AUTOSAR XML (schema 314)
# Copyright © Vector Informatik GmbH 2011
# Please contact Vector Informatik whenever you need further information concerning the license conditions.
package /VehicleProject
  system System: fibex-element=[CAN00, LIN00, FlexRay, MyECU, MyECU, MyECU__CAN00_Rx, MyECU__CAN00_Tx, MyECU__FlexRay_Rx, MyECU__FlexRay_Tx, MyECU__LIN00_Rx, MyECU__LIN00_Tx, Dummy_RearECU, Frame_LinTr_MyECU__LIN00, Frame_LinTr_RearECU__LIN00, MasterReq__LIN00, msg_diag_Request_MyECU__CAN00, msg_diag_RequestGlobal__CAN00, msg_diag_Response_MyECU__CAN00, msg_diag_Uudt_Response_MyECU__CAN00, msg_nm_MyECU__CAN00, msg_Receive__CAN00, msg_TxCycle10__CAN00, msg_TxMulti100__CAN00, msg_XCP_Request__CAN00, msg_XCP_Response__CAN00, nm_MyECU_Fr, SlaveResp__LIN00, TpRouting_Rx, TpRouting_Tx, Transmit_MyECU, Frame_LinTr_MyECU__LIN00, Frame_LinTr_RearECU__LIN00, msg_Receive__CAN00, msg_TxCycle10__CAN00, msg_TxMulti100_Mx00__CAN00, msg_TxMulti100_Mx01__CAN00, msg_XCP_Request__CAN00, msg_XCP_Response__CAN00, PDU_Dummy_RearECU, PDU_Transmit_MyECU, msg_TxMulti100__CAN00, MasterReq__LIN00, msg_diag_Request_MyECU__CAN00, msg_diag_RequestGlobal__CAN00, msg_diag_Response_MyECU__CAN00, msg_diag_Uudt_Response_MyECU__CAN00, SlaveResp__LIN00, msg_nm_MyECU__CAN00, PDU_nm_MyECU_Fr, MasterReq_Tp__LIN00, msg_diag_Request_MyECU_Tp__CAN00, msg_diag_RequestGlobal_Tp__CAN00, msg_diag_Response_MyECU_Tp__CAN00, msg_diag_Uudt_Response_MyECU_Tp__CAN00, PDU_TpRouting_Rx_Tp, PDU_TpRouting_Tx_Tp, SlaveResp_Tp__LIN00, Sig_ErrBit_RearECU__Frame_LinTr_RearECU__LIN00, Sig_LinTr_MyECU__Frame_LinTr_MyECU__LIN00, Sig_LinTr_RearECU__Frame_LinTr_RearECU__LIN00, Signal_Dummy__PDU_Dummy_RearECU, Signal_RearInteriorLight__msg_Receive__CAN00, Signal_RearLeftDoor__msg_Receive__CAN00, Signal_RearRightDoor__msg_Receive__CAN00, Signal_SwitchRearInteriorLight__PDU_Transmit_MyECU, Signal_TxCycle10__msg_TxCycle10__CAN00, Signal_TxMulti_0_0_Mx00__msg_TxMulti100__CAN00, Signal_TxMulti0_1_Mx00__msg_TxMulti100__CAN00, Signal_TxMulti0_2_Mx00__msg_TxMulti100__CAN00, Signal_TxMulti0_3_Mx00__msg_TxMulti100__CAN00, Signal_TxMulti1_0_Mx01__msg_TxMulti100__CAN00, Signal_TxMulti1_1_Mx01__msg_TxMulti100__CAN00, Signal_TxMulti1_2_Mx01__msg_TxMulti100__CAN00, Signal_TxMulti1_3_Mx01__msg_TxMulti100__CAN00, Signal_TxMulti1_4_Mx01__msg_TxMulti100__CAN00, Signal_TxMultiplexor_Mx00__msg_TxMulti100__CAN00, Signal_TxMultiplexor_Mx01__msg_TxMulti100__CAN00]
package /Cluster
  can cluster CAN00: protocol-name=CAN, speed=500000, nm-lower-can-id=1024, nm-repeat-message-state-time=0.4, nm-timeout-time=1, nm-upper-can-id=1087, nm-wait-bus-sleep-time=0.75
    physical channel CHNL
      frame msg_diag_Request_MyECU__CAN00: id 0x610, frame-length=8, can-addressing-mode=STANDARD
        n pdu msg_diag_Request_MyECU_Tp__CAN00: length=64
      frame msg_diag_RequestGlobal__CAN00: id 0x614, frame-length=8, can-addressing-mode=STANDARD
        n pdu msg_diag_RequestGlobal_Tp__CAN00: length=64
      frame msg_diag_Response_MyECU__CAN00: id 0x612, frame-length=8, can-addressing-mode=STANDARD
        n pdu msg_diag_Response_MyECU_Tp__CAN00: length=64
      frame msg_diag_Uudt_Response_MyECU__CAN00: id 0x616, frame-length=8, can-addressing-mode=STANDARD
        n pdu msg_diag_Uudt_Response_MyECU_Tp__CAN00: length=64
      frame msg_nm_MyECU__CAN00: id 0x400, frame-length=8, can-addressing-mode=STANDARD
        nm pdu msg_nm_MyECU__CAN00: length=64
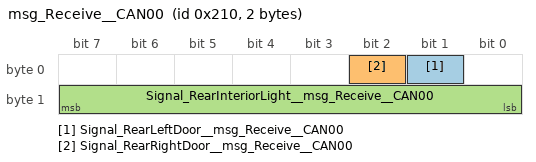
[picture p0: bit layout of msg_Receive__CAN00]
      frame msg_Receive__CAN00: id 0x210, frame-length=2, can-addressing-mode=STANDARD
        pdu msg_Receive__CAN00: length=16, cyclic-timing={repeating-time=0.1, starting-time=0}, minimum-delay=0, transmission-mode-false-timing=cyclic-timing={repeating-time=0.1, starting-time=0}
          signal Signal_RearLeftDoor__msg_Receive__CAN00: start 1, 1 bit, little-endian, data-type=DT_Signal_RearLeftDoor, init-value=C_Signal_RearLeftDoor, transfer-property=PENDING
          signal Signal_RearRightDoor__msg_Receive__CAN00: start 2, 1 bit, little-endian, data-type=DT_Signal_RearRightDoor, init-value=C_Signal_RearRightDoor, transfer-property=PENDING
          signal Signal_RearInteriorLight__msg_Receive__CAN00: start 8, 8 bit, little-endian, data-type=DT_Signal_RearInteriorLight, init-value=C_Signal_RearInteriorLight, transfer-property=PENDING
      frame msg_TxCycle10__CAN00: id 0x268, frame-length=8, can-addressing-mode=STANDARD
        pdu msg_TxCycle10__CAN00: length=64, cyclic-timing={repeating-time=0.01, starting-time=0}, minimum-delay=0, transmission-mode-false-timing=cyclic-timing={repeating-time=0.01, starting-time=0}
          signal Signal_TxCycle10__msg_TxCycle10__CAN00: start 0, 32 bit, little-endian, data-type=DT_Signal_TxCycle10, init-value=C_Signal_TxCycle10, transfer-property=PENDING
      frame msg_TxMulti100__CAN00: id 0x266, frame-length=8, can-addressing-mode=STANDARD
        multiplexed i pdu msg_TxMulti100__CAN00:
          length=64
          dynamic-part={segment-position{segment-byte-order=little-endian, segment-length=48, segment-position=0}, dynamic-part-alternatives=[{i-pdu=msg_TxMulti100_Mx00__CAN00, initial-dynamic-part=true, selector-field-code=0}, {i-pdu=msg_TxMulti100_Mx01__CAN00, initial-dynamic-part=false, selector-field-code=1}]}
          selector-field-byte-order=little-endian
          selector-field-length=3
          selector-field-start-position=0
      frame msg_XCP_Request__CAN00: id 0x703, frame-length=8, can-addressing-mode=STANDARD
        pdu msg_XCP_Request__CAN00: length=64
      frame msg_XCP_Response__CAN00: id 0x704, frame-length=8, can-addressing-mode=STANDARD
        pdu msg_XCP_Response__CAN00: length=64
      pdu triggering PT_msg_diag_Request_MyECU: pdu=msg_diag_Request_MyECU__CAN00
      pdu triggering PT_msg_diag_RequestGlobal: pdu=msg_diag_RequestGlobal__CAN00
      pdu triggering PT_msg_diag_Response_MyECU: pdu=msg_diag_Response_MyECU__CAN00
      pdu triggering PT_msg_diag_Uudt_Response_MyECU: pdu=msg_diag_Uudt_Response_MyECU__CAN00
      pdu triggering PT_msg_TxMulti100_Mx00: pdu=msg_TxMulti100_Mx00__CAN00
      pdu triggering PT_msg_TxMulti100_Mx01: pdu=msg_TxMulti100_Mx01__CAN00
      tp-channels:
        addressing-format=STANDARD, data-pdu=msg_diag_RequestGlobal_Tp__CAN00, multicast-addressing=true, padding-activation=true, tp-sdu=msg_diag_RequestGlobal__CAN00
        addressing-format=STANDARD, data-pdu=msg_diag_Response_MyECU_Tp__CAN00, flow-control-pdu=msg_diag_Request_MyECU_Tp__CAN00, multicast-addressing=false, padding-activation=true, source=CN_CAN00, tp-sdu=msg_diag_Response_MyECU__CAN00
        addressing-format=STANDARD, data-pdu=msg_diag_Request_MyECU_Tp__CAN00, flow-control-pdu=msg_diag_Response_MyECU_Tp__CAN00, multicast-addressing=false, padding-activation=true, target=CN_CAN00, tp-sdu=msg_diag_Request_MyECU__CAN00
  lin cluster LIN00: protocol-name=LIN, protocol-version=2.0, speed=19200  # /*************************************************************************************/ // // Description: LIN Description file created using Vector's DaVinci Network Designer // Created: 07 Jul 2009 09:46:32 // Author: vishgo // Version: 0.0 // /*************************************************************************************/
    physical channel CHNL
      frame Frame_LinTr_MyECU__LIN00: id 0x11, from MyECU, frame-length=1, checksum-type=CLASSIC, relatively-scheduled-timing{delay=0.005, position-in-table=0, schedule-table=Normal}
        pdu Frame_LinTr_MyECU__LIN00: length=8
          signal Sig_LinTr_MyECU__Frame_LinTr_MyECU__LIN00: start 0, 8 bit, little-endian, data-type=DT_Sig_LinTr_MyECU, init-value=C_Sig_LinTr_MyECU
      frame Frame_LinTr_RearECU__LIN00: id 0x12, to MyECU, frame-length=1, checksum-type=CLASSIC, relatively-scheduled-timing{delay=0.005, position-in-table=1, schedule-table=Normal}
        pdu Frame_LinTr_RearECU__LIN00: length=8
          signal Sig_LinTr_RearECU__Frame_LinTr_RearECU__LIN00: start 0, 7 bit, little-endian, data-type=DT_Sig_LinTr_RearECU, init-value=C_Sig_LinTr_RearECU, to MyECU
          signal Sig_ErrBit_RearECU__Frame_LinTr_RearECU__LIN00: start 7, 1 bit, little-endian, data-type=DT_Sig_ErrBit_RearECU, init-value=C_Sig_ErrBit_RearECU, to MyECU
      frame MasterReq__LIN00: id 0x3C, from MyECU, frame-length=8, checksum-type=CLASSIC, relatively-scheduled-timing{delay=0.08, position-in-table=0, schedule-table=Diagnose}
        n pdu MasterReq_Tp__LIN00: length=64
      frame SlaveResp__LIN00: id 0x3D, to MyECU, frame-length=8, checksum-type=CLASSIC, relatively-scheduled-timing{delay=0.08, position-in-table=1, schedule-table=Diagnose}
        n pdu SlaveResp_Tp__LIN00: length=64
      pdu triggering PT_MasterReq: pdu=MasterReq__LIN00, from MyECU
      pdu triggering PT_SlaveResp: pdu=SlaveResp__LIN00, to MyECU
    lin schedule table Diagnose: priority=255, run-mode=RUN-CONTINUOUS
    lin schedule table Normal: priority=255, run-mode=RUN-CONTINUOUS
  flexray cluster FlexRay:
    protocol-name=FlexRay
    protocol-version=3.0
    speed=10000000
    action-point-offset=3
    bit=1E-07
    cas-rx-low-max=99
    cold-start-attempts=31
    cycle=0.005
    dynamic-slot-idle-phase=1
    listen-noise=2
    macro-per-cycle=5000
    macrotick-duration=1E-06
    max-initialisation-error=3.024E-06
    max-without-clock-correction-fatal=1
    max-without-clock-correction-passive=1
    minislot-action-point-offset=3
    minislot-duration=7
    network-idle-time=105
    network-management-vector-length=0
    number-of-minislots=267
    number-of-static-slots=89
    offset-correction-start=4956
    payload-length-static=8
    sample-clock-period=1.25E-08
    static-slot-duration=34
    symbol-window=0
    sync-node-max=9
    transmission-start-sequence-duration=15
    wake-up-symbol-rx-idle=59
    wake-up-symbol-rx-low=55
    wake-up-symbol-rx-window=301
    wake-up-symbol-tx-idle=180
    wake-up-symbol-tx-low=60
    flexray physical channel Channel_A: channel-name=CHANNEL-A
      frame Transmit_MyECU: from MyECU, frame-length=8, absolutely-scheduled-timing{communication-cycle=cycle-repetition={base-cycle=0, cycle-repetition=CYCLE-REPETITION-1}, slot-id=2}
        pdu PDU_Transmit_MyECU: length=64, cyclic-timing=repeating-time=0.1
          signal Signal_SwitchRearInteriorLight__PDU_Transmit_MyECU: start 0, 8 bit, little-endian, data-type=New_Coding_1, init-value=C_Signal_SwitchRearInteriorLight
      frame Dummy_RearECU: to MyECU, frame-length=16, absolutely-scheduled-timing{communication-cycle=cycle-repetition={base-cycle=0, cycle-repetition=CYCLE-REPETITION-1}, slot-id=3}
        pdu PDU_Dummy_RearECU: length=128, cyclic-timing=repeating-time=0.1
          signal Signal_Dummy__PDU_Dummy_RearECU: start 0, 8 bit, little-endian, data-type=New_Coding_2, init-value=C_Signal_Dummy, to MyECU
      frame nm_MyECU_Fr: from MyECU, frame-length=8, absolutely-scheduled-timing{communication-cycle=cycle-repetition={base-cycle=0, cycle-repetition=CYCLE-REPETITION-64}, slot-id=90}
        nm pdu PDU_nm_MyECU_Fr: length=64
      frame TpRouting_Tx: from MyECU, frame-length=16, absolutely-scheduled-timing{communication-cycle=cycle-repetition={base-cycle=0, cycle-repetition=CYCLE-REPETITION-4}, slot-id=97}
        n pdu PDU_TpRouting_Tx_Tp: length=128
      frame TpRouting_Rx: to MyECU, frame-length=16, absolutely-scheduled-timing{communication-cycle=cycle-repetition={base-cycle=0, cycle-repetition=CYCLE-REPETITION-4}, slot-id=99}
        n pdu PDU_TpRouting_Rx_Tp: length=128
package /ECU
  ecu instance MyECU: associated-i-pdu-group=[MyECU__CAN00_Rx, MyECU__CAN00_Tx, MyECU__FlexRay_Rx, MyECU__FlexRay_Tx, MyECU__LIN00_Rx, MyECU__LIN00_Tx], com-processing-period=0.001
    flexray communication controller MyECU:
      accepted-startup-range=242
      allow-halt-due-to-clock=true
      allow-passive-to-active=0
      cluster-drift-damping=2
      decoding-correction=72
      delay-compensation-a=1
      delay-compensation-b=1
      extern-offset-correction=0
      extern-rate-correction=0
      key-slot-id=2
      key-slot-used-for-start-up=true
      key-slot-used-for-sync=true
      latest-tx=1
      listen-timeout=401202
      macro-initial-offset-a=5
      macro-initial-offset-b=5
      max-drift=601
      maximum-dynamic-payload-length=127
      micro-initial-offset-a=7
      micro-initial-offset-b=7
      micro-per-cycle=200000
      microtick-duration=2.5E-08
      offset-correction-out=150
      rate-correction-out=601
      samples-per-microtick=2
      single-slot-enabled=false
      wake-up-pattern=63
    lin master CT_LIN00: time-base=0.001, time-base-jitter=0
    communication connector CN_LIN00: channel=LIN00/CHNL, comm-controller=CT_LIN00
    flex ray communication connector CN_Channel_A: channel=Channel_A, comm-controller=MyECU, wake-up-channel=false
package /Gateway
  gateway MyECU: ecu=MyECU
package /IPDUGroup
  6 x i pdu group:
    MyECU__CAN00_Rx: communication-direction=IN, i-pdu=msg_Receive__CAN00
    MyECU__CAN00_Tx: communication-direction=OUT, i-pdu=[msg_TxCycle10__CAN00, msg_TxMulti100_Mx00__CAN00, msg_TxMulti100_Mx01__CAN00]
    MyECU__FlexRay_Rx: communication-direction=IN, i-pdu=PDU_Dummy_RearECU
    MyECU__FlexRay_Tx: communication-direction=OUT, i-pdu=PDU_Transmit_MyECU
    MyECU__LIN00_Rx: communication-direction=IN, i-pdu=Frame_LinTr_RearECU__LIN00
    MyECU__LIN00_Tx: communication-direction=OUT, i-pdu=Frame_LinTr_MyECU__LIN00
package /PDU
  pdu msg_TxMulti100_Mx00__CAN00: length=64, cyclic-timing={repeating-time=0.2, starting-time=0}, minimum-delay=0
    signal Signal_TxMultiplexor_Mx00__msg_TxMulti100__CAN00: start 0, 3 bit, little-endian, data-type=DT_Signal_TxMultiplexor, init-value=C_Signal_TxMultiplexor_Mx00, transfer-property=PENDING
    signal Signal_TxMulti_0_0_Mx00__msg_TxMulti100__CAN00: start 8, 2 bit, little-endian, data-type=DT_Signal_TxMulti_0_0, init-value=C_Signal_TxMulti_0_0, transfer-property=PENDING
    signal Signal_TxMulti0_1_Mx00__msg_TxMulti100__CAN00: start 16, 8 bit, little-endian, data-type=DT_Signal_TxMulti0_1, init-value=C_Signal_TxMulti0_1, transfer-property=PENDING
    signal Signal_TxMulti0_2_Mx00__msg_TxMulti100__CAN00: start 24, 4 bit, little-endian, data-type=DT_Signal_TxMulti0_2, init-value=C_Signal_TxMulti0_2, transfer-property=PENDING
    signal Signal_TxMulti0_3_Mx00__msg_TxMulti100__CAN00: start 32, 8 bit, little-endian, data-type=DT_Signal_TxMulti0_3, init-value=C_Signal_TxMulti0_3, transfer-property=PENDING
  pdu msg_TxMulti100_Mx01__CAN00: length=64, cyclic-timing={repeating-time=0.2, starting-time=0.1}, minimum-delay=0
    signal Signal_TxMultiplexor_Mx01__msg_TxMulti100__CAN00: start 0, 3 bit, little-endian, data-type=DT_Signal_TxMultiplexor, init-value=C_Signal_TxMultiplexor_Mx01, transfer-property=PENDING
    signal Signal_TxMulti1_0_Mx01__msg_TxMulti100__CAN00: start 8, 8 bit, little-endian, data-type=DT_Signal_TxMulti1_0, init-value=C_Signal_TxMulti1_0, transfer-property=PENDING
    signal Signal_TxMulti1_1_Mx01__msg_TxMulti100__CAN00: start 16, 8 bit, little-endian, data-type=DT_Signal_TxMulti1_1, init-value=C_Signal_TxMulti1_1, transfer-property=PENDING
    signal Signal_TxMulti1_2_Mx01__msg_TxMulti100__CAN00: start 24, 8 bit, little-endian, data-type=DT_Signal_TxMulti1_2, init-value=C_Signal_TxMulti1_2, transfer-property=PENDING
    signal Signal_TxMulti1_3_Mx01__msg_TxMulti100__CAN00: start 32, 8 bit, little-endian, data-type=DT_Signal_TxMulti1_3, init-value=C_Signal_TxMulti1_3, transfer-property=PENDING
    signal Signal_TxMulti1_4_Mx01__msg_TxMulti100__CAN00: start 40, 8 bit, little-endian, data-type=DT_Signal_TxMulti1_4, init-value=C_Signal_TxMulti1_4, transfer-property=PENDING
  dcm i pdu MasterReq__LIN00: length=64
  dcm i pdu msg_diag_Request_MyECU__CAN00: length=64
  dcm i pdu msg_diag_RequestGlobal__CAN00: length=64
  dcm i pdu msg_diag_Response_MyECU__CAN00: length=64
  dcm i pdu msg_diag_Uudt_Response_MyECU__CAN00: length=64
  dcm i pdu SlaveResp__LIN00: length=64
package /DataType
  boolean type DT_Sig_ErrBit_RearECU
  boolean type DT_Signal_RearLeftDoor
  boolean type DT_Signal_RearRightDoor
  16 x integer type, all with lower-limit=0:
    DT_Sig_LinTr_MyECU: upper-limit=255
    DT_Sig_LinTr_RearECU: upper-limit=127
    DT_Signal_RearInteriorLight: upper-limit=255
    DT_Signal_TxCycle10: upper-limit=4294967295
    DT_Signal_TxMulti_0_0: upper-limit=3
    DT_Signal_TxMulti0_1: upper-limit=255
    DT_Signal_TxMulti0_2: upper-limit=15
    DT_Signal_TxMulti0_3: upper-limit=255
    DT_Signal_TxMulti1_{0..4}: upper-limit=255
    DT_Signal_TxMultiplexor: upper-limit=7
    New_Coding_1: upper-limit=255
    New_Coding_2: upper-limit=255
package /Constant
  20 x constant specification:
    C_Sig_ErrBit_RearECU
      value:
        boolean literal C_Sig_ErrBit_RearECU: type=DT_Sig_ErrBit_RearECU, value=false
    C_Signal_RearLeftDoor
      value:
        boolean literal C_Signal_RearLeftDoor: type=DT_Signal_RearLeftDoor, value=false
    C_Signal_RearRightDoor
      value:
        boolean literal C_Signal_RearRightDoor: type=DT_Signal_RearRightDoor, value=false
    C_Sig_LinTr_MyECU
      value:
        integer literal C_Sig_LinTr_MyECU: type=DT_Sig_LinTr_MyECU, value=0
    C_Sig_LinTr_RearECU
      value:
        integer literal C_Sig_LinTr_RearECU: type=DT_Sig_LinTr_RearECU, value=0
    C_Signal_Dummy
      value:
        integer literal C_Signal_Dummy: type=New_Coding_2, value=0
    C_Signal_RearInteriorLight
      value:
        integer literal C_Signal_RearInteriorLight: type=DT_Signal_RearInteriorLight, value=0
    C_Signal_SwitchRearInteriorLight
      value:
        integer literal C_Signal_SwitchRearInteriorLight: type=New_Coding_1, value=0
    C_Signal_TxCycle10
      value:
        integer literal C_Signal_TxCycle10: type=DT_Signal_TxCycle10, value=0
    C_Signal_TxMulti_0_0
      value:
        integer literal C_Signal_TxMulti_0_0: type=DT_Signal_TxMulti_0_0, value=0
    C_Signal_TxMulti0_1
      value:
        integer literal C_Signal_TxMulti0_1: type=DT_Signal_TxMulti0_1, value=1
    C_Signal_TxMulti0_2
      value:
        integer literal C_Signal_TxMulti0_2: type=DT_Signal_TxMulti0_2, value=2
    C_Signal_TxMulti0_3
      value:
        integer literal C_Signal_TxMulti0_3: type=DT_Signal_TxMulti0_3, value=3
    C_Signal_TxMulti1_0
      value:
        integer literal C_Signal_TxMulti1_0: type=DT_Signal_TxMulti1_0, value=16
    C_Signal_TxMulti1_1
      value:
        integer literal C_Signal_TxMulti1_1: type=DT_Signal_TxMulti1_1, value=17
    C_Signal_TxMulti1_2
      value:
        integer literal C_Signal_TxMulti1_2: type=DT_Signal_TxMulti1_2, value=18
    C_Signal_TxMulti1_3
      value:
        integer literal C_Signal_TxMulti1_3: type=DT_Signal_TxMulti1_3, value=19
    C_Signal_TxMulti1_4
      value:
        integer literal C_Signal_TxMulti1_4: type=DT_Signal_TxMulti1_4, value=20
    C_Signal_TxMultiplexor_Mx00
      value:
        integer literal C_Signal_TxMultiplexor_Mx00: type=DT_Signal_TxMultiplexor, value=0
    C_Signal_TxMultiplexor_Mx01
      value:
        integer literal C_Signal_TxMultiplexor_Mx01: type=DT_Signal_TxMultiplexor, value=1
